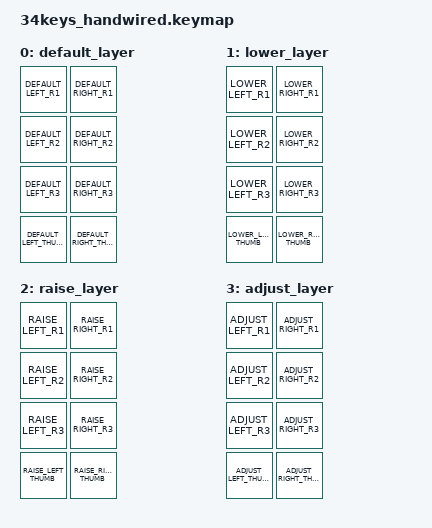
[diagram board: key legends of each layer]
// Copyright (c) 2022 The ZMK Contributors
// SPDX-License-Identifier: MIT

#include <behaviors.dtsi>
#include <dt-bindings/zmk/bt.h>
#include <dt-bindings/zmk/keys.h>

#include "defaults/layout.h"
#include "defaults/keypos/34keys.h"

#include "defaults/behaviors.dtsi"

/ {
    conditional_layers {
        compatible = "zmk,conditional-layers";
        tri_layer {
            if-layers = <1 2>;
            then-layer = <3>;
        };
    };

    combos {
       #include "defaults/combos.dtsi"
    };

    macros {
        #include "defaults/macros.dtsi"
    };

    keymap {
    compatible = "zmk,keymap";

        default_layer {
            bindings = <
DEFAULT_LEFT_R1       DEFAULT_RIGHT_R1
DEFAULT_LEFT_R2       DEFAULT_RIGHT_R2
DEFAULT_LEFT_R3       DEFAULT_RIGHT_R3
DEFAULT_LEFT_THUMB    DEFAULT_RIGHT_THUMB
            >;
        };

        lower_layer {
            bindings = <
LOWER_LEFT_R1       LOWER_RIGHT_R1
LOWER_LEFT_R2       LOWER_RIGHT_R2
LOWER_LEFT_R3       LOWER_RIGHT_R3
LOWER_LEFT_THUMB    LOWER_RIGHT_THUMB
            >;
        };

        raise_layer {
            bindings = <
RAISE_LEFT_R1       RAISE_RIGHT_R1
RAISE_LEFT_R2       RAISE_RIGHT_R2
RAISE_LEFT_R3       RAISE_RIGHT_R3
RAISE_LEFT_THUMB    RAISE_RIGHT_THUMB
            >;
        };

        adjust_layer {
            bindings = <
ADJUST_LEFT_R1          ADJUST_RIGHT_R1
ADJUST_LEFT_R2          ADJUST_RIGHT_R2
ADJUST_LEFT_R3          ADJUST_RIGHT_R3
    ADJUST_LEFT_THUMB   ADJUST_RIGHT_THUMB
            >;
        };
    };
};
